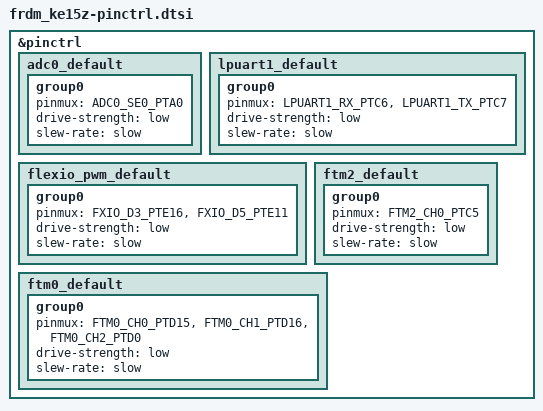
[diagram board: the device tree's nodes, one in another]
/*
 * Copyright 2024 NXP
 * SPDX-License-Identifier: Apache-2.0
 */

#include <nxp/kinetis/MKE15Z256VLL7-pinctrl.h>

&pinctrl {
	adc0_default: adc0_default {
		group0 {
			pinmux = <ADC0_SE0_PTA0>;
			drive-strength = "low";
			slew-rate = "slow";
		};
	};

	lpuart1_default: lpuart1_default {
		group0 {
			pinmux = <LPUART1_RX_PTC6>,
				 <LPUART1_TX_PTC7>;
			drive-strength = "low";
			slew-rate = "slow";
		};
	};

	flexio_pwm_default: flexio_pwm_default {
		group0 {
			pinmux = <FXIO_D3_PTE16>,
				 <FXIO_D5_PTE11>;
			drive-strength = "low";
			slew-rate = "slow";
		};
	};

	ftm2_default: ftm2_default {
		group0 {
			pinmux = <FTM2_CH0_PTC5>;
			drive-strength = "low";
			slew-rate = "slow";
		};
	};

	ftm0_default: ftm0_default {
		group0 {
			pinmux = <FTM0_CH0_PTD15>,
				 <FTM0_CH1_PTD16>,
				 <FTM0_CH2_PTD0>;
			drive-strength = "low";
			slew-rate = "slow";
		};
	};
};
